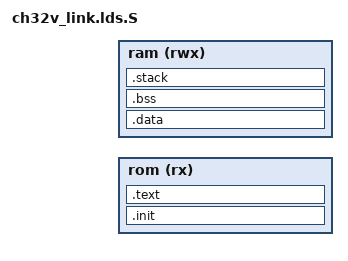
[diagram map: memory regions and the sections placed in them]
// CH32V RISC-V linker script

#include "autoconf.h" // CONFIG_FLASH_APPLICATION_ADDRESS

OUTPUT_FORMAT("elf32-littleriscv", "elf32-littleriscv", "elf32-littleriscv")
OUTPUT_ARCH(riscv)

MEMORY
{
  rom (rx) : ORIGIN = CONFIG_FLASH_APPLICATION_ADDRESS , LENGTH = CONFIG_FLASH_SIZE
  ram (rwx) : ORIGIN = CONFIG_RAM_START , LENGTH = CONFIG_RAM_SIZE
}

SECTIONS
{
    .init : {
        . = ALIGN(4);
        KEEP(*(.init))
        KEEP(*(.vector_table))
    } > rom

    .text : {
        . = ALIGN(4);
        *(.text .text.*)
        *(.rodata .rodata*)
    } > rom

    . = ALIGN(4);
    _data_flash = .;

    .data : AT (_data_flash)
    {
        . = ALIGN(4);
        _data_start = .;
        *(.ramfunc .ramfunc.*);
        *(.data .data.*);
        *(.sdata .sdata.*);
        . = ALIGN(4);
        _data_end = .;
    } > ram

    /* RISC-V global pointer for small data addressing */
    __global_pointer$ = _data_start + 0x800;

    .bss (NOLOAD) :
    {
        . = ALIGN(4);
        _bss_start = .;
        *(.bss .bss.*)
        *(.sbss .sbss.*)
        *(COMMON)
        . = ALIGN(4);
        _bss_end = .;
    } > ram

    _stack_start = CONFIG_RAM_START + CONFIG_RAM_SIZE - CONFIG_STACK_SIZE ;
    .stack _stack_start (NOLOAD) :
    {
        . = . + CONFIG_STACK_SIZE;
        _stack_end = .;
    } > ram

    /DISCARD/ : {
        *(.init)
        *(.fini)
        *(.riscv.attributes)
    }
}

